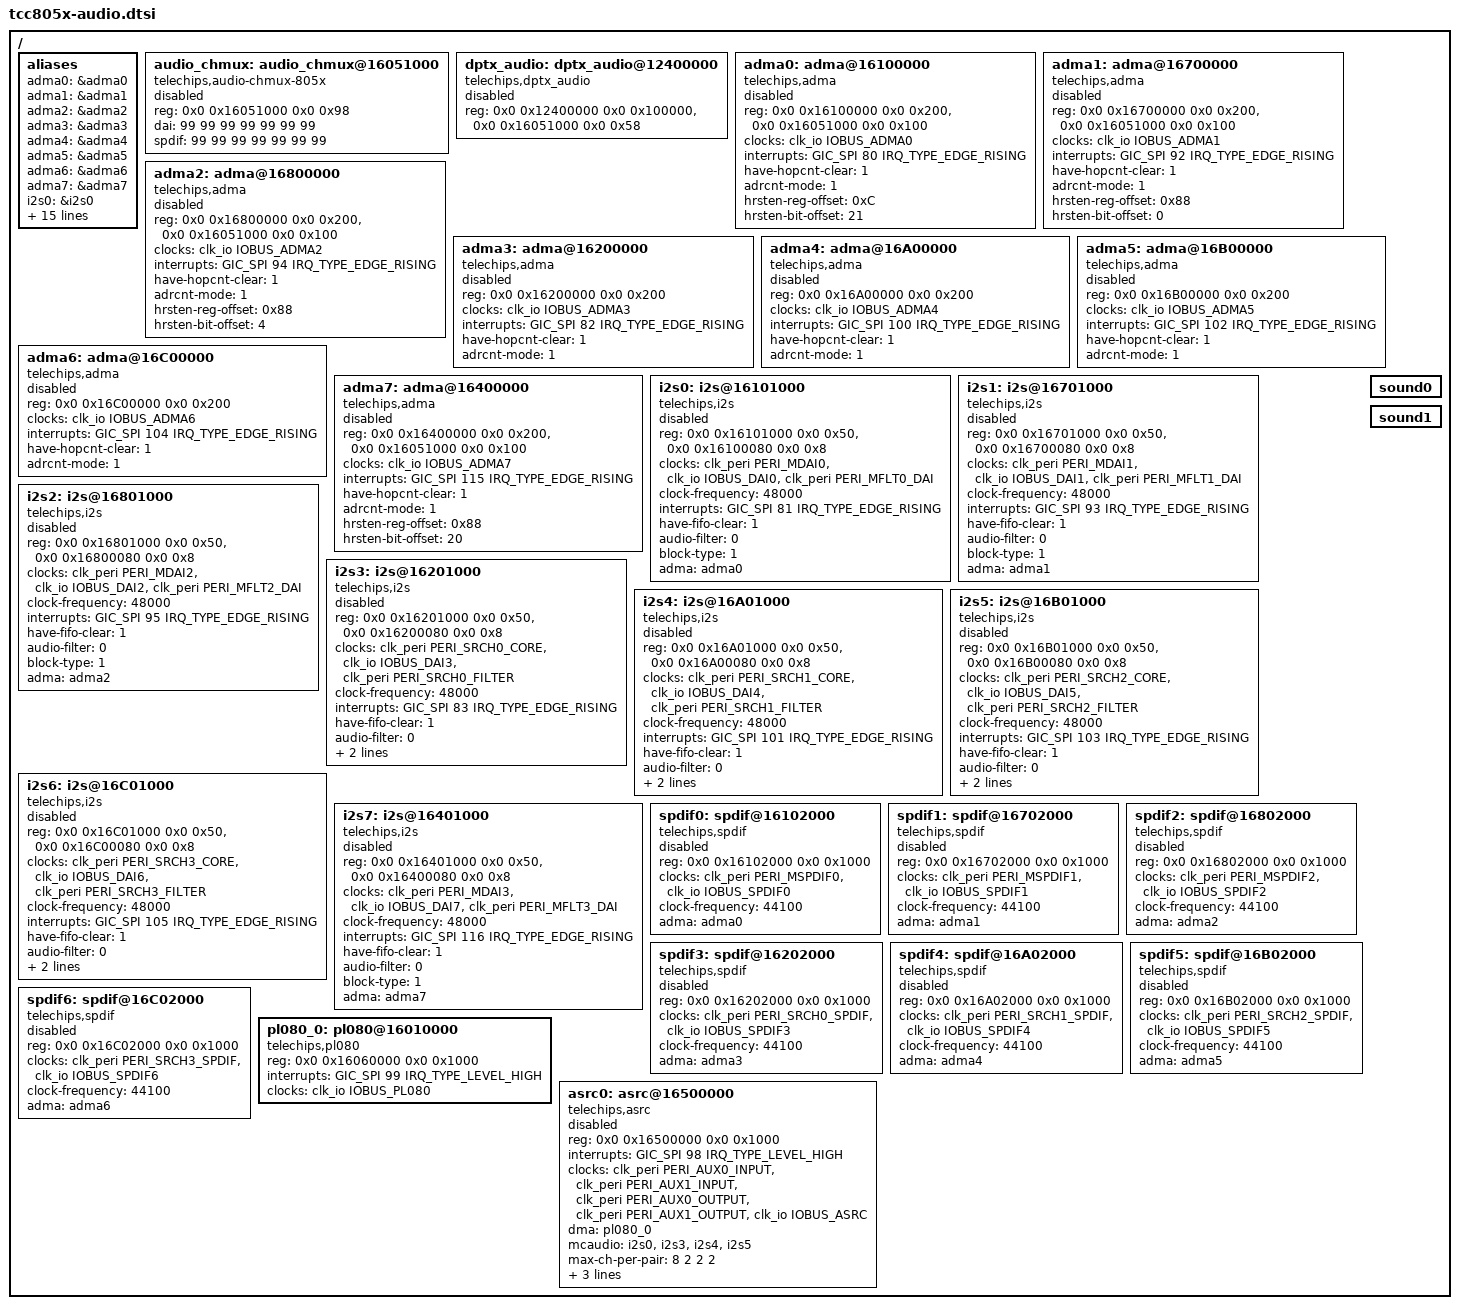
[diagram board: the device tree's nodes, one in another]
/* SPDX-License-Identifier: (GPL-2.0-or-later OR MIT) */
/*
 * Copyright (C) 2023 Telechips Inc.
 */

#include <dt-bindings/interrupt-controller/arm-gic.h>
#include <dt-bindings/clock/telechips,tcc805x-clks.h>

/ {
	aliases: aliases {
		adma0  = &adma0;
		adma1  = &adma1;
		adma2  = &adma2;
		adma3  = &adma3;
		adma4  = &adma4;
		adma5  = &adma5;
		adma6  = &adma6;
		adma7  = &adma7;
		i2s0 = &i2s0;
		i2s1 = &i2s1;
		i2s2 = &i2s2;
		i2s3 = &i2s3;
		i2s4 = &i2s4;
		i2s5 = &i2s5;
		i2s6 = &i2s6;
		i2s7 = &i2s7;
		spdif0 = &spdif0;
		spdif1 = &spdif1;
		spdif2 = &spdif2;
		spdif3 = &spdif3;
		spdif4 = &spdif4;
		spdif5 = &spdif5;
		spdif6 = &spdif6;
		asrc0  = &asrc0;
	};
	audio_chmux: audio_chmux@16051000{
		compatible = "telechips,audio-chmux-805x";
		reg = <0x0 0x16051000 0x0 0x98>;
		dai = <99 99 99 99 99 99 99>;
		//i2s0(x) i2s1(x) i2s2(x) i2s3(x) i2s4(x) i2s5(x) i2s6(x)
		spdif = <99 99 99 99 99 99 99>;
		//spdif0(x) spdif1(x) spdif2(x) spdif3(x) spdif4(x) spdif5(x) spdif6(x)
		status = "disabled";
	};

	dptx_audio: dptx_audio@12400000 {
		compatible = "telechips,dptx_audio";
		reg = <0x0 0x12400000 0x0 0x100000>, <0x0 0x16051000 0x0 0x58>;
		status = "disabled";
	};

	adma0: adma@16100000 {
		compatible = "telechips,adma";
		reg = <0x0 0x16100000 0x0 0x200>,
			<0x0 0x16051000 0x0 0x100>;
		clocks = <&clk_io IOBUS_ADMA0>;
		interrupts = <GIC_SPI 80 IRQ_TYPE_EDGE_RISING>;
		have-hopcnt-clear = <1>;
		adrcnt-mode = <1>;
		hrsten-reg-offset = <0xC>;
		hrsten-bit-offset = <21>;
		status = "disabled";
	};

	adma1: adma@16700000 {
		compatible = "telechips,adma";
		reg = <0x0 0x16700000 0x0 0x200>,
			<0x0 0x16051000 0x0 0x100>;
		clocks = <&clk_io IOBUS_ADMA1>;
		interrupts = <GIC_SPI 92 IRQ_TYPE_EDGE_RISING>;
		have-hopcnt-clear = <1>;
		adrcnt-mode = <1>;
		hrsten-reg-offset = <0x88>;
		hrsten-bit-offset = <0>;
		status = "disabled";
	};

	adma2: adma@16800000 {
		compatible = "telechips,adma";
		reg = <0x0 0x16800000 0x0 0x200>,
			<0x0 0x16051000 0x0 0x100>;
		clocks = <&clk_io IOBUS_ADMA2>;
		interrupts = <GIC_SPI 94 IRQ_TYPE_EDGE_RISING>;
		have-hopcnt-clear = <1>;
		adrcnt-mode = <1>;
		hrsten-reg-offset = <0x88>;
		hrsten-bit-offset = <4>;
		status = "disabled";
	};

	adma3: adma@16200000 {
		compatible = "telechips,adma";
		reg = <0x0 0x16200000 0x0 0x200>;
		clocks = <&clk_io IOBUS_ADMA3>;
		interrupts = <GIC_SPI 82 IRQ_TYPE_EDGE_RISING>;
		have-hopcnt-clear = <1>;
		adrcnt-mode = <1>;
		status = "disabled";
	};

	adma4: adma@16A00000 {
		compatible = "telechips,adma";
		reg = <0x0 0x16A00000 0x0 0x200>;
		clocks = <&clk_io IOBUS_ADMA4>;
		interrupts = <GIC_SPI 100 IRQ_TYPE_EDGE_RISING>;
		have-hopcnt-clear = <1>;
		adrcnt-mode = <1>;
		status = "disabled";
	};

	adma5: adma@16B00000 {
		compatible = "telechips,adma";
		reg = <0x0 0x16B00000 0x0 0x200>;
		clocks = <&clk_io IOBUS_ADMA5>;
		interrupts = <GIC_SPI 102 IRQ_TYPE_EDGE_RISING>;
		have-hopcnt-clear = <1>;
		adrcnt-mode = <1>;
		status = "disabled";
	};

	adma6: adma@16C00000 {
		compatible = "telechips,adma";
		reg = <0x0 0x16C00000 0x0 0x200>;
		clocks = <&clk_io IOBUS_ADMA6>;
		interrupts = <GIC_SPI 104 IRQ_TYPE_EDGE_RISING>;
		have-hopcnt-clear = <1>;
		adrcnt-mode = <1>;
		status = "disabled";
	};

	adma7: adma@16400000 {
		compatible = "telechips,adma";
		reg = <0x0 0x16400000 0x0 0x200>,
			<0x0 0x16051000 0x0 0x100>;
		clocks = <&clk_io IOBUS_ADMA7>;
		interrupts = <GIC_SPI 115 IRQ_TYPE_EDGE_RISING>;
		have-hopcnt-clear = <1>;
		adrcnt-mode = <1>;
		hrsten-reg-offset = <0x88>;
		hrsten-bit-offset = <20>;
		status = "disabled";
	};

	i2s0: i2s@16101000 {
		compatible = "telechips,i2s";
		reg = <0x0 0x16101000 0x0 0x50>,
		      <0x0 0x16100080 0x0 0x8>;
		clocks = <&clk_peri PERI_MDAI0 &clk_io IOBUS_DAI0
				&clk_peri PERI_MFLT0_DAI>;
		clock-frequency = <48000>;	// Default LRCK
		interrupts = <GIC_SPI 81 IRQ_TYPE_EDGE_RISING>;
		have-fifo-clear = <1>;
		audio-filter = <0>;
		// 0: disable, 1: clock only, 2: data only, 3: data and clock
		block-type = <1>; // 0: SI2S 1: MI2S
		adma = <&adma0>;
		status = "disabled";
	};

	i2s1: i2s@16701000 {
		compatible = "telechips,i2s";
		reg = <0x0 0x16701000 0x0 0x50>,
		      <0x0 0x16700080 0x0 0x8>;
		clocks = <&clk_peri PERI_MDAI1 &clk_io IOBUS_DAI1
				&clk_peri PERI_MFLT1_DAI>;
		clock-frequency = <48000>;	// Default LRCK
		interrupts = <GIC_SPI 93 IRQ_TYPE_EDGE_RISING>;
		have-fifo-clear = <1>;
		audio-filter = <0>;
		// 0: disable, 1: clock only, 2: data only, 3: data and clock
		block-type = <1>; // 0: SI2S 1: MI2S
		adma = <&adma1>;
		status = "disabled";
	};

	i2s2: i2s@16801000 {
		compatible = "telechips,i2s";
		reg = <0x0 0x16801000 0x0 0x50>,
		      <0x0 0x16800080 0x0 0x8>;
		clocks = <&clk_peri PERI_MDAI2 &clk_io IOBUS_DAI2
				&clk_peri PERI_MFLT2_DAI>;
		clock-frequency = <48000>;	// Default LRCK
		interrupts = <GIC_SPI 95 IRQ_TYPE_EDGE_RISING>;
		have-fifo-clear = <1>;
		audio-filter = <0>;
		// 0: disable, 1: clock only, 2: data only, 3: data and clock
		block-type = <1>; // 0: SI2S 1: MI2S
		adma = <&adma2>;
		status = "disabled";
	};

	i2s3: i2s@16201000 {
		compatible = "telechips,i2s";
		reg = <0x0 0x16201000 0x0 0x50>,
		      <0x0 0x16200080 0x0 0x8>;
		clocks = <&clk_peri PERI_SRCH0_CORE &clk_io IOBUS_DAI3
				&clk_peri PERI_SRCH0_FILTER>;
		clock-frequency = <48000>;	// Default LRCK
		interrupts = <GIC_SPI 83 IRQ_TYPE_EDGE_RISING>;
		have-fifo-clear = <1>;
		audio-filter = <0>;
		// 0: disable, 1: clock only, 2: data only, 3: data and clock
		block-type = <0>; // 0: SI2S 1: MI2S
		adma = <&adma3>;
		status = "disabled";
	};

	i2s4: i2s@16A01000 {
		compatible = "telechips,i2s";
		reg = <0x0 0x16A01000 0x0 0x50>,
		      <0x0 0x16A00080 0x0 0x8>;
		clocks = <&clk_peri PERI_SRCH1_CORE &clk_io IOBUS_DAI4
				&clk_peri PERI_SRCH1_FILTER>;
		clock-frequency = <48000>;	// Default LRCK
		interrupts = <GIC_SPI 101 IRQ_TYPE_EDGE_RISING>;
		have-fifo-clear = <1>;
		audio-filter = <0>;
		// 0: disable, 1: clock only, 2: data only, 3: data and clock
		block-type = <0>; // 0: SI2S 1: MI2S
		adma = <&adma4>;
		status = "disabled";
	};

	i2s5: i2s@16B01000 {
		compatible = "telechips,i2s";
		reg = <0x0 0x16B01000 0x0 0x50>,
		      <0x0 0x16B00080 0x0 0x8>;
		clocks = <&clk_peri PERI_SRCH2_CORE &clk_io IOBUS_DAI5
				&clk_peri PERI_SRCH2_FILTER>;
		clock-frequency = <48000>;	// Default LRCK
		interrupts = <GIC_SPI 103 IRQ_TYPE_EDGE_RISING>;
		have-fifo-clear = <1>;
		audio-filter = <0>;
		// 0: disable, 1: clock only, 2: data only, 3: data and clock
		block-type = <0>; // 0: SI2S 1: MI2S
		adma = <&adma5>;
		status = "disabled";
	};

	i2s6: i2s@16C01000 {
		compatible = "telechips,i2s";
		reg = <0x0 0x16C01000 0x0 0x50>,
		      <0x0 0x16C00080 0x0 0x8>;
		clocks = <&clk_peri PERI_SRCH3_CORE &clk_io IOBUS_DAI6
				&clk_peri PERI_SRCH3_FILTER>;
		clock-frequency = <48000>;	// Default LRCK
		interrupts = <GIC_SPI 105 IRQ_TYPE_EDGE_RISING>;
		have-fifo-clear = <1>;
		audio-filter = <0>;
		// 0: disable, 1: clock only, 2: data only, 3: data and clock
		block-type = <0>; // 0: SI2S 1: MI2S
		adma = <&adma6>;
		status = "disabled";
	};

	i2s7: i2s@16401000 {
		compatible = "telechips,i2s";
		reg = <0x0 0x16401000 0x0 0x50>,
		      <0x0 0x16400080 0x0 0x8>;
		clocks = <&clk_peri PERI_MDAI3 &clk_io IOBUS_DAI7
				&clk_peri PERI_MFLT3_DAI>;
		clock-frequency = <48000>;	// Default LRCK
		interrupts = <GIC_SPI 116 IRQ_TYPE_EDGE_RISING>;
		have-fifo-clear = <1>;
		audio-filter = <0>;
		// 0: disable, 1: clock only, 2: data only, 3: data and clock
		block-type = <1>; // 0: SI2S 1: MI2S
		adma = <&adma7>;
		status = "disabled";
	};

	spdif0: spdif@16102000 {
		compatible = "telechips,spdif";
		reg = <0x0 0x16102000 0x0 0x1000>;
		clocks = <&clk_peri PERI_MSPDIF0 &clk_io IOBUS_SPDIF0>;
		clock-frequency = <44100>;
		adma = <&adma0>;
		status = "disabled";
	};

	spdif1: spdif@16702000 {
		compatible = "telechips,spdif";
		reg = <0x0 0x16702000 0x0 0x1000>;
		clocks = <&clk_peri PERI_MSPDIF1 &clk_io IOBUS_SPDIF1>;
		clock-frequency = <44100>;
		adma = <&adma1>;
		status = "disabled";
	};

	spdif2: spdif@16802000 {
		compatible = "telechips,spdif";
		reg = <0x0 0x16802000 0x0 0x1000>;
		clocks = <&clk_peri PERI_MSPDIF2 &clk_io IOBUS_SPDIF2>;
		clock-frequency = <44100>;
		adma = <&adma2>;
		status = "disabled";
	};

	spdif3: spdif@16202000 {
		compatible = "telechips,spdif";
		reg = <0x0 0x16202000 0x0 0x1000>;
		clocks = <&clk_peri PERI_SRCH0_SPDIF &clk_io IOBUS_SPDIF3>;
		clock-frequency = <44100>;
		adma = <&adma3>;
		status = "disabled";
	};

	spdif4: spdif@16A02000 {
		compatible = "telechips,spdif";
		reg = <0x0 0x16A02000 0x0 0x1000>;
		clocks = <&clk_peri PERI_SRCH1_SPDIF &clk_io IOBUS_SPDIF4>;
		clock-frequency = <44100>;
		adma = <&adma4>;
		status = "disabled";
	};

	spdif5: spdif@16B02000 {
		compatible = "telechips,spdif";
		reg = <0x0 0x16B02000 0x0 0x1000>;
		clocks = <&clk_peri PERI_SRCH2_SPDIF &clk_io IOBUS_SPDIF5>;
		clock-frequency = <44100>;
		adma = <&adma5>;
		status = "disabled";
	};

	spdif6: spdif@16C02000 {
		compatible = "telechips,spdif";
		reg = <0x0 0x16C02000 0x0 0x1000>;
		clocks = <&clk_peri PERI_SRCH3_SPDIF &clk_io IOBUS_SPDIF6>;
		clock-frequency = <44100>;
		adma = <&adma6>;
		status = "disabled";
	};

	pl080_0: pl080@16010000 {
		compatible = "telechips,pl080";
		reg = <0x0 0x16060000 0x0 0x1000>;
		interrupts = <GIC_SPI 99 IRQ_TYPE_LEVEL_HIGH>;
		clocks = <&clk_io IOBUS_PL080>;
		clock-names = "pl080_hclk";
	};

	asrc0: asrc@16500000 {
		compatible = "telechips,asrc";
		reg = <0x0 0x16500000 0x0 0x1000>;
		interrupts = <GIC_SPI 98 IRQ_TYPE_LEVEL_HIGH>;
		clocks = <&clk_peri PERI_AUX0_INPUT
				&clk_peri PERI_AUX1_INPUT
				&clk_peri PERI_AUX0_OUTPUT
				&clk_peri PERI_AUX1_OUTPUT
				&clk_io IOBUS_ASRC>;
		clock-names = "aux_in0", "aux_in1",
					"aux_out0", "aux_out1", "asrc_hclk";
		dma = <&pl080_0>;
		mcaudio = <&i2s0 &i2s3 &i2s4 &i2s5>;
		max-ch-per-pair= <8 2 2 2>;
		path-type = <0 0 0 0>; // 0:m2m, 1:m2p, 2:p2m
		sync-mode = <1 1 1 1>; // 0:async, 1:sync
		async-refclk = <99 99 99 99>;
		//0:DAI0_LRCK, 1:DAI1_LRCK, 2:DAI2_LRCK, 3:DAI3_LRCK, 99:AUXCLK
		status = "disabled";
	};

	sound0: sound0 {};
	sound1: sound1 {};
};
